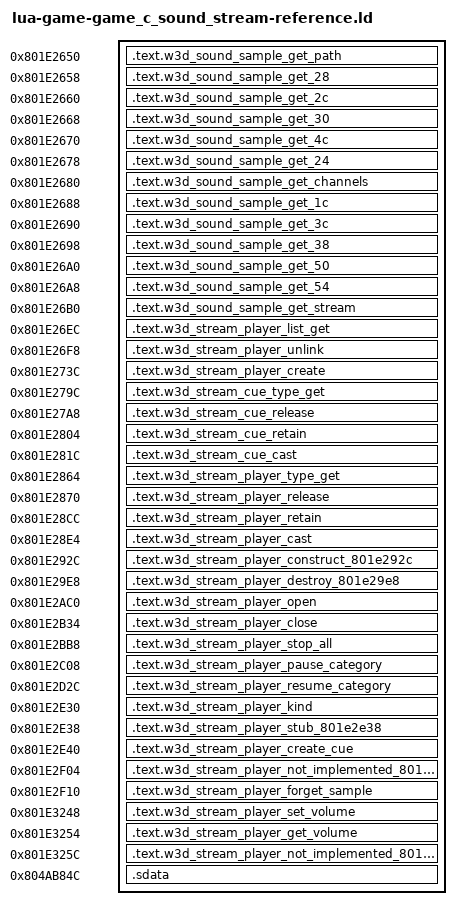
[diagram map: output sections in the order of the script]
/* Generated reference-only placements. All bodies are source-built. */
OUTPUT_FORMAT("elf32-powerpc")
OUTPUT_ARCH(powerpc)
ENTRY(w3d_sound_sample_get_path)
_SDA_BASE_ = 0x804b2540;
_SDA2_BASE_ = 0x804c2540;
w3d_actor_member_delete_backend = 0x801fe1f8;
w3d_actor_node_destroy = 0x80210990;
w3d_f32_803b0654 = 0x803b0654;
w3d_handle_storage_release = 0x802134fc;
w3d_heap_allocate_entry_a = 0x801fe1d8;
w3d_owner_list_remove = 0x8020fd2c;
w3d_sound_sample_get_44 = 0x801e25d4;
w3d_state_register = 0x8020fd04;
w3d_stream_channel_construct_801e5a60 = 0x801e5a60;
w3d_stream_channel_pause_801e5f24 = 0x801e5f24;
w3d_stream_channel_resume_801e5f84 = 0x801e5f84;
w3d_stream_channel_setup_801e5b7c = 0x801e5b7c;
w3d_stream_channel_stop_801e5dfc = 0x801e5dfc;
w3d_stream_cue_destroy_801e3528 = 0x801e3528;
w3d_stream_cue_detach_801e3824 = 0x801e3824;
w3d_stream_cue_type_803b0624 = 0x803b0624;
w3d_stream_cue_unlink_801e37b0 = 0x801e37b0;
w3d_stream_member_close_801e4020 = 0x801e4020;
w3d_stream_member_construct_801e3f00 = 0x801e3f00;
w3d_stream_member_destroy_801e3f0c = 0x801e3f0c;
w3d_stream_member_open_801e3f3c = 0x801e3f3c;
w3d_stream_player_base_vtable_80416d78 = 0x80416d78;
w3d_stream_player_list_8036570c = 0x8036570c;
w3d_stream_player_new_cue_801e3268 = 0x801e3268;
w3d_stream_player_type_803b063c = 0x803b063c;
w3d_stream_player_vtable_80416e88 = 0x80416e88;
w3d_type_cast_8020b460 = 0x8020b460;
SECTIONS {
  .text.w3d_sound_sample_get_path 0x801e2650 : { *(.text.w3d_sound_sample_get_path) }
  .text.w3d_sound_sample_get_28 0x801e2658 : { *(.text.w3d_sound_sample_get_28) }
  .text.w3d_sound_sample_get_2c 0x801e2660 : { *(.text.w3d_sound_sample_get_2c) }
  .text.w3d_sound_sample_get_30 0x801e2668 : { *(.text.w3d_sound_sample_get_30) }
  .text.w3d_sound_sample_get_4c 0x801e2670 : { *(.text.w3d_sound_sample_get_4c) }
  .text.w3d_sound_sample_get_24 0x801e2678 : { *(.text.w3d_sound_sample_get_24) }
  .text.w3d_sound_sample_get_channels 0x801e2680 : { *(.text.w3d_sound_sample_get_channels) }
  .text.w3d_sound_sample_get_1c 0x801e2688 : { *(.text.w3d_sound_sample_get_1c) }
  .text.w3d_sound_sample_get_3c 0x801e2690 : { *(.text.w3d_sound_sample_get_3c) }
  .text.w3d_sound_sample_get_38 0x801e2698 : { *(.text.w3d_sound_sample_get_38) }
  .text.w3d_sound_sample_get_50 0x801e26a0 : { *(.text.w3d_sound_sample_get_50) }
  .text.w3d_sound_sample_get_54 0x801e26a8 : { *(.text.w3d_sound_sample_get_54) }
  .text.w3d_sound_sample_get_stream 0x801e26b0 : { *(.text.w3d_sound_sample_get_stream) }
  .text.w3d_stream_player_list_get 0x801e26ec : { *(.text.w3d_stream_player_list_get) }
  .text.w3d_stream_player_unlink 0x801e26f8 : { *(.text.w3d_stream_player_unlink) }
  .text.w3d_stream_player_create 0x801e273c : { *(.text.w3d_stream_player_create) }
  .text.w3d_stream_cue_type_get 0x801e279c : { *(.text.w3d_stream_cue_type_get) }
  .text.w3d_stream_cue_release 0x801e27a8 : { *(.text.w3d_stream_cue_release) }
  .text.w3d_stream_cue_retain 0x801e2804 : { *(.text.w3d_stream_cue_retain) }
  .text.w3d_stream_cue_cast 0x801e281c : { *(.text.w3d_stream_cue_cast) }
  .text.w3d_stream_player_type_get 0x801e2864 : { *(.text.w3d_stream_player_type_get) }
  .text.w3d_stream_player_release 0x801e2870 : { *(.text.w3d_stream_player_release) }
  .text.w3d_stream_player_retain 0x801e28cc : { *(.text.w3d_stream_player_retain) }
  .text.w3d_stream_player_cast 0x801e28e4 : { *(.text.w3d_stream_player_cast) }
  .text.w3d_stream_player_construct_801e292c 0x801e292c : { *(.text.w3d_stream_player_construct_801e292c) }
  .text.w3d_stream_player_destroy_801e29e8 0x801e29e8 : { *(.text.w3d_stream_player_destroy_801e29e8) }
  .text.w3d_stream_player_open 0x801e2ac0 : { *(.text.w3d_stream_player_open) }
  .text.w3d_stream_player_close 0x801e2b34 : { *(.text.w3d_stream_player_close) }
  .text.w3d_stream_player_stop_all 0x801e2bb8 : { *(.text.w3d_stream_player_stop_all) }
  .text.w3d_stream_player_pause_category 0x801e2c08 : { *(.text.w3d_stream_player_pause_category) }
  .text.w3d_stream_player_resume_category 0x801e2d2c : { *(.text.w3d_stream_player_resume_category) }
  .text.w3d_stream_player_kind 0x801e2e30 : { *(.text.w3d_stream_player_kind) }
  .text.w3d_stream_player_stub_801e2e38 0x801e2e38 : { *(.text.w3d_stream_player_stub_801e2e38) }
  .text.w3d_stream_player_create_cue 0x801e2e40 : { *(.text.w3d_stream_player_create_cue) }
  .text.w3d_stream_player_not_implemented_801e2f04 0x801e2f04 : { *(.text.w3d_stream_player_not_implemented_801e2f04) }
  .text.w3d_stream_player_forget_sample 0x801e2f10 : { *(.text.w3d_stream_player_forget_sample) }
  .text.w3d_stream_player_set_volume 0x801e3248 : { *(.text.w3d_stream_player_set_volume) }
  .text.w3d_stream_player_get_volume 0x801e3254 : { *(.text.w3d_stream_player_get_volume) }
  .text.w3d_stream_player_not_implemented_801e325c 0x801e325c : { *(.text.w3d_stream_player_not_implemented_801e325c) }
  .sdata 0x804ab84c (NOLOAD) : {
    . = 0x0; w3d_stream_player_current_804ab84c = .;
    . += 1; }
  /DISCARD/ : { *(.text*) *(.rodata*) *(.data*) *(.bss*) *(.sdata*) *(.sbss*) *(.comment) }
}
